# ESP32-C3 register map
Vendor: ESPRESSIF SYSTEMS (SHANGHAI) CO., LTD.; Series: ESP32 C-Series; File version: 18
CPU: RV32IMC r0p0, little endian, no MPU, no FPU, 0 interrupt priority bits
Address unit: 32 bits
Registers are 32-bit, read-write, reset 0x0 unless marked. A register's access mark holds for its fields unless they carry their own. Offsets are from the block's base; [hi:lo] are bit positions.

## EXTMEM — External Memory
Base 0x600C4000
0x00 ICACHE_CTRL — This description will be updated in the near future.
  [0] ICACHE_ENABLE — The bit is used to activate the data cache. 0: disable, 1: enable
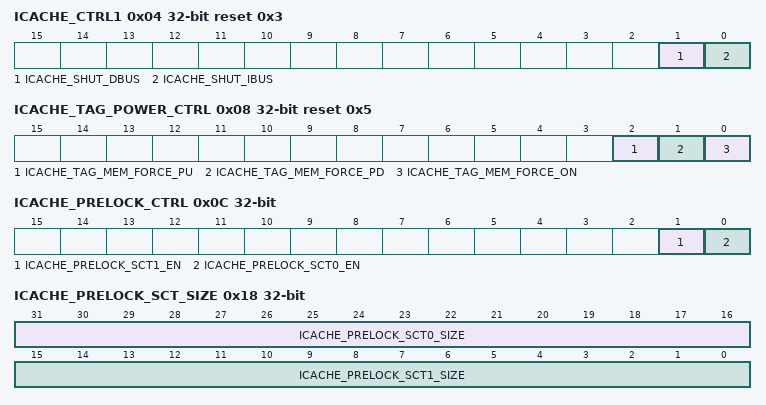
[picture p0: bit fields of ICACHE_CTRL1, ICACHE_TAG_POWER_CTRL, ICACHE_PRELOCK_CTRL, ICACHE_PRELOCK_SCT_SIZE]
0x04 ICACHE_CTRL1 reset 0x3 — This description will be updated in the near future.
  [1] ICACHE_SHUT_DBUS — The bit is used to disable core1 ibus, 0: enable, 1: disable
  [0] ICACHE_SHUT_IBUS — The bit is used to disable core0 ibus, 0: enable, 1: disable
0x08 ICACHE_TAG_POWER_CTRL reset 0x5 — This description will be updated in the near future.
  [2] ICACHE_TAG_MEM_FORCE_PU — The bit is used to power icache tag memory up, 0: follow rtc_lslp, 1: power up
  [1] ICACHE_TAG_MEM_FORCE_PD — The bit is used to power icache tag memory down, 0: follow rtc_lslp, 1: power down
  [0] ICACHE_TAG_MEM_FORCE_ON — The bit is used to close clock gating of icache tag memory. 1: close gating, 0: open clock gating.
0x0C ICACHE_PRELOCK_CTRL — This description will be updated in the near future.
  [1] ICACHE_PRELOCK_SCT1_EN — The bit is used to enable the second section of prelock function.
  [0] ICACHE_PRELOCK_SCT0_EN — The bit is used to enable the first section of prelock function.
0x10 ICACHE_PRELOCK_SCT0_ADDR — This description will be updated in the near future.
  [31:0] ICACHE_PRELOCK_SCT0_ADDR — The bits are used to configure the first start virtual address of data prelock, which is combined with ICACHE_PRELOCK_SCT0_SIZE_REG
0x14 ICACHE_PRELOCK_SCT1_ADDR — This description will be updated in the near future.
  [31:0] ICACHE_PRELOCK_SCT1_ADDR — The bits are used to configure the second start virtual address of data prelock, which is combined with ICACHE_PRELOCK_SCT1_SIZE_REG
0x18 ICACHE_PRELOCK_SCT_SIZE — This description will be updated in the near future.
  [31:16] ICACHE_PRELOCK_SCT0_SIZE — The bits are used to configure the first length of data locking, which is combined with ICACHE_PRELOCK_SCT0_ADDR_REG
  [15:0] ICACHE_PRELOCK_SCT1_SIZE — The bits are used to configure the second length of data locking, which is combined with ICACHE_PRELOCK_SCT1_ADDR_REG
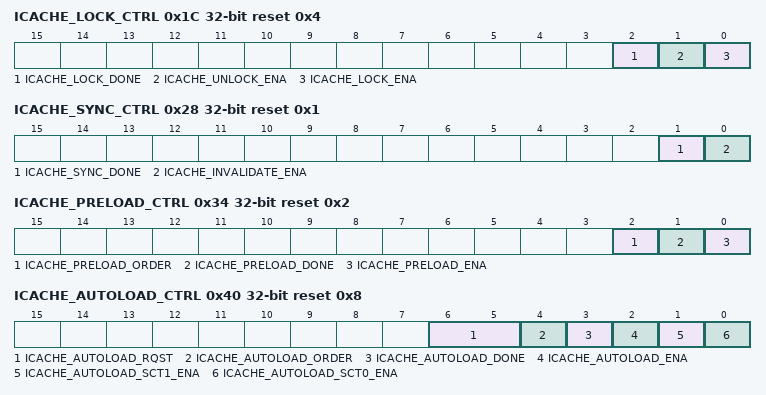
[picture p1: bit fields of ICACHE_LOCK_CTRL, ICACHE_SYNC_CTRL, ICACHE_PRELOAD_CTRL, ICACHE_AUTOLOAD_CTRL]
0x1C ICACHE_LOCK_CTRL access per field reset 0x4 — This description will be updated in the near future.
  [2] ICACHE_LOCK_DONE ro — The bit is used to indicate unlock/lock operation is finished.
  [1] ICACHE_UNLOCK_ENA rw — The bit is used to enable unlock operation. It will be cleared by hardware after unlock operation done.
  [0] ICACHE_LOCK_ENA rw — The bit is used to enable lock operation. It will be cleared by hardware after lock operation done.
0x20 ICACHE_LOCK_ADDR — This description will be updated in the near future.
  [31:0] ICACHE_LOCK_ADDR — The bits are used to configure the start virtual address for lock operations. It should be combined with ICACHE_LOCK_SIZE_REG.
0x24 ICACHE_LOCK_SIZE — This description will be updated in the near future.
  [15:0] ICACHE_LOCK_SIZE — The bits are used to configure the length for lock operations. The bits are the counts of cache block. It should be combined with ICACHE_LOCK_ADDR_REG.
0x28 ICACHE_SYNC_CTRL access per field reset 0x1 — This description will be updated in the near future.
  [1] ICACHE_SYNC_DONE ro — The bit is used to indicate invalidate operation is finished.
  [0] ICACHE_INVALIDATE_ENA rw — The bit is used to enable invalidate operation. It will be cleared by hardware after invalidate operation done.
0x2C ICACHE_SYNC_ADDR — This description will be updated in the near future.
  [31:0] ICACHE_SYNC_ADDR — The bits are used to configure the start virtual address for clean operations. It should be combined with ICACHE_SYNC_SIZE_REG.
0x30 ICACHE_SYNC_SIZE — This description will be updated in the near future.
  [22:0] ICACHE_SYNC_SIZE — The bits are used to configure the length for sync operations. The bits are the counts of cache block. It should be combined with ICACHE_SYNC_ADDR_REG.
0x34 ICACHE_PRELOAD_CTRL access per field reset 0x2 — This description will be updated in the near future.
  [2] ICACHE_PRELOAD_ORDER rw — The bit is used to configure the direction of preload operation. 1: descending, 0: ascending.
  [1] ICACHE_PRELOAD_DONE ro — The bit is used to indicate preload operation is finished.
  [0] ICACHE_PRELOAD_ENA rw — The bit is used to enable preload operation. It will be cleared by hardware after preload operation done.
0x38 ICACHE_PRELOAD_ADDR — This description will be updated in the near future.
  [31:0] ICACHE_PRELOAD_ADDR — The bits are used to configure the start virtual address for preload operation. It should be combined with ICACHE_PRELOAD_SIZE_REG.
0x3C ICACHE_PRELOAD_SIZE — This description will be updated in the near future.
  [15:0] ICACHE_PRELOAD_SIZE — The bits are used to configure the length for preload operation. The bits are the counts of cache block. It should be combined with ICACHE_PRELOAD_ADDR_REG..
0x40 ICACHE_AUTOLOAD_CTRL access per field reset 0x8 — This description will be updated in the near future.
  [6:5] ICACHE_AUTOLOAD_RQST rw — The bits are used to configure trigger conditions for autoload. 0/3: cache miss, 1: cache hit, 2: both cache miss and hit.
  [4] ICACHE_AUTOLOAD_ORDER rw — The bits are used to configure the direction of autoload. 1: descending, 0: ascending.
  [3] ICACHE_AUTOLOAD_DONE ro — The bit is used to indicate autoload operation is finished.
  [2] ICACHE_AUTOLOAD_ENA rw — The bit is used to enable and disable autoload operation. It is combined with icache_autoload_done. 1: enable, 0: disable.
  [1] ICACHE_AUTOLOAD_SCT1_ENA rw — The bits are used to enable the second section for autoload operation.
  [0] ICACHE_AUTOLOAD_SCT0_ENA rw — The bits are used to enable the first section for autoload operation.
0x44 ICACHE_AUTOLOAD_SCT0_ADDR — This description will be updated in the near future.
  [31:0] ICACHE_AUTOLOAD_SCT0_ADDR — The bits are used to configure the start virtual address of the first section for autoload operation. It should be combined with icache_autoload_sct0_ena.
0x48 ICACHE_AUTOLOAD_SCT0_SIZE — This description will be updated in the near future.
  [26:0] ICACHE_AUTOLOAD_SCT0_SIZE — The bits are used to configure the length of the first section for autoload operation. It should be combined with icache_autoload_sct0_ena.
0x4C ICACHE_AUTOLOAD_SCT1_ADDR — This description will be updated in the near future.
  [31:0] ICACHE_AUTOLOAD_SCT1_ADDR — The bits are used to configure the start virtual address of the second section for autoload operation. It should be combined with icache_autoload_sct1_ena.
0x50 ICACHE_AUTOLOAD_SCT1_SIZE — This description will be updated in the near future.
  [26:0] ICACHE_AUTOLOAD_SCT1_SIZE — The bits are used to configure the length of the second section for autoload operation. It should be combined with icache_autoload_sct1_ena.
0x54 IBUS_TO_FLASH_START_VADDR reset 0x42000000 — This description will be updated in the near future.
  [31:0] IBUS_TO_FLASH_START_VADDR — The bits are used to configure the start virtual address of ibus to access flash. The register is used to give constraints to ibus access counter.
0x58 IBUS_TO_FLASH_END_VADDR reset 0x427FFFFF — This description will be updated in the near future.
  [31:0] IBUS_TO_FLASH_END_VADDR — The bits are used to configure the end virtual address of ibus to access flash. The register is used to give constraints to ibus access counter.
0x5C DBUS_TO_FLASH_START_VADDR reset 0x3C000000 — This description will be updated in the near future.
  [31:0] DBUS_TO_FLASH_START_VADDR — The bits are used to configure the start virtual address of dbus to access flash. The register is used to give constraints to dbus access counter.
0x60 DBUS_TO_FLASH_END_VADDR reset 0x3C7FFFFF — This description will be updated in the near future.
  [31:0] DBUS_TO_FLASH_END_VADDR — The bits are used to configure the end virtual address of dbus to access flash. The register is used to give constraints to dbus access counter.
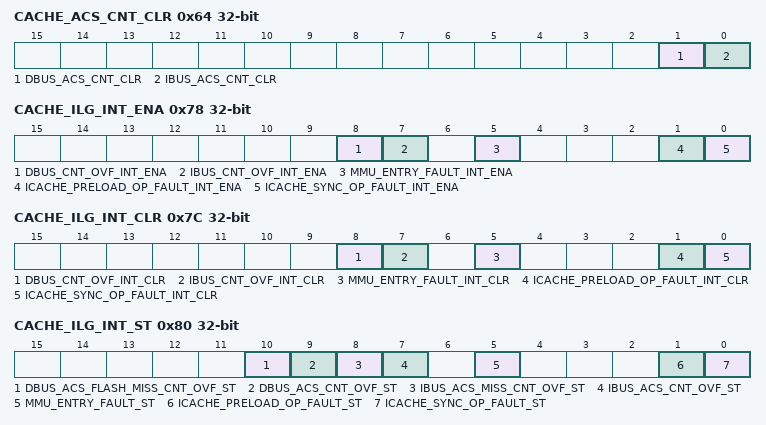
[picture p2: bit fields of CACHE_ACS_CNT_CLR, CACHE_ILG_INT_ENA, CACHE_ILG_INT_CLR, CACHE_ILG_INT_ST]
0x64 CACHE_ACS_CNT_CLR wo — This description will be updated in the near future.
  [1] DBUS_ACS_CNT_CLR — The bit is used to clear dbus counter.
  [0] IBUS_ACS_CNT_CLR — The bit is used to clear ibus counter.
0x68 IBUS_ACS_MISS_CNT ro — This description will be updated in the near future.
  [31:0] IBUS_ACS_MISS_CNT — The bits are used to count the number of the cache miss caused by ibus access flash.
0x6C IBUS_ACS_CNT ro — This description will be updated in the near future.
  [31:0] IBUS_ACS_CNT — The bits are used to count the number of ibus access flash through icache.
0x70 DBUS_ACS_FLASH_MISS_CNT ro — This description will be updated in the near future.
  [31:0] DBUS_ACS_FLASH_MISS_CNT — The bits are used to count the number of the cache miss caused by dbus access flash.
0x74 DBUS_ACS_CNT ro — This description will be updated in the near future.
  [31:0] DBUS_ACS_CNT — The bits are used to count the number of dbus access flash through icache.
0x78 CACHE_ILG_INT_ENA — This description will be updated in the near future.
  [8] DBUS_CNT_OVF_INT_ENA — The bit is used to enable interrupt by dbus counter overflow.
  [7] IBUS_CNT_OVF_INT_ENA — The bit is used to enable interrupt by ibus counter overflow.
  [5] MMU_ENTRY_FAULT_INT_ENA — The bit is used to enable interrupt by mmu entry fault.
  [1] ICACHE_PRELOAD_OP_FAULT_INT_ENA — The bit is used to enable interrupt by preload configurations fault.
  [0] ICACHE_SYNC_OP_FAULT_INT_ENA — The bit is used to enable interrupt by sync configurations fault.
0x7C CACHE_ILG_INT_CLR wo — This description will be updated in the near future.
  [8] DBUS_CNT_OVF_INT_CLR — The bit is used to clear interrupt by dbus counter overflow.
  [7] IBUS_CNT_OVF_INT_CLR — The bit is used to clear interrupt by ibus counter overflow.
  [5] MMU_ENTRY_FAULT_INT_CLR — The bit is used to clear interrupt by mmu entry fault.
  [1] ICACHE_PRELOAD_OP_FAULT_INT_CLR — The bit is used to clear interrupt by preload configurations fault.
  [0] ICACHE_SYNC_OP_FAULT_INT_CLR — The bit is used to clear interrupt by sync configurations fault.
0x80 CACHE_ILG_INT_ST ro — This description will be updated in the near future.
  [10] DBUS_ACS_FLASH_MISS_CNT_OVF_ST — The bit is used to indicate interrupt by dbus access flash miss counter overflow.
  [9] DBUS_ACS_CNT_OVF_ST — The bit is used to indicate interrupt by dbus access flash/spiram counter overflow.
  [8] IBUS_ACS_MISS_CNT_OVF_ST — The bit is used to indicate interrupt by ibus access flash/spiram miss counter overflow.
  [7] IBUS_ACS_CNT_OVF_ST — The bit is used to indicate interrupt by ibus access flash/spiram counter overflow.
  [5] MMU_ENTRY_FAULT_ST — The bit is used to indicate interrupt by mmu entry fault.
  [1] ICACHE_PRELOAD_OP_FAULT_ST — The bit is used to indicate interrupt by preload configurations fault.
  [0] ICACHE_SYNC_OP_FAULT_ST — The bit is used to indicate interrupt by sync configurations fault.
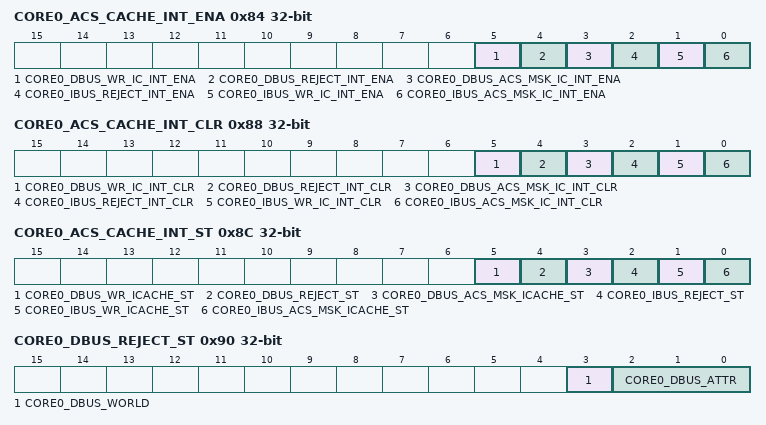
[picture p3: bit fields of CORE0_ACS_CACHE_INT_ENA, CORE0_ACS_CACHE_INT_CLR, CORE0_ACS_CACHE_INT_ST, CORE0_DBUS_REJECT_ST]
0x84 CORE0_ACS_CACHE_INT_ENA — This description will be updated in the near future.
  [5] CORE0_DBUS_WR_IC_INT_ENA — The bit is used to enable interrupt by dbus trying to write icache
  [4] CORE0_DBUS_REJECT_INT_ENA — The bit is used to enable interrupt by authentication fail.
  [3] CORE0_DBUS_ACS_MSK_IC_INT_ENA — The bit is used to enable interrupt by cpu access icache while the corresponding dbus is disabled which include speculative access.
  [2] CORE0_IBUS_REJECT_INT_ENA — The bit is used to enable interrupt by authentication fail.
  [1] CORE0_IBUS_WR_IC_INT_ENA — The bit is used to enable interrupt by ibus trying to write icache
  [0] CORE0_IBUS_ACS_MSK_IC_INT_ENA — The bit is used to enable interrupt by cpu access icache while the corresponding ibus is disabled which include speculative access.
0x88 CORE0_ACS_CACHE_INT_CLR wo — This description will be updated in the near future.
  [5] CORE0_DBUS_WR_IC_INT_CLR — The bit is used to clear interrupt by dbus trying to write icache
  [4] CORE0_DBUS_REJECT_INT_CLR — The bit is used to clear interrupt by authentication fail.
  [3] CORE0_DBUS_ACS_MSK_IC_INT_CLR — The bit is used to clear interrupt by cpu access icache while the corresponding dbus is disabled or icache is disabled which include speculative access.
  [2] CORE0_IBUS_REJECT_INT_CLR — The bit is used to clear interrupt by authentication fail.
  [1] CORE0_IBUS_WR_IC_INT_CLR — The bit is used to clear interrupt by ibus trying to write icache
  [0] CORE0_IBUS_ACS_MSK_IC_INT_CLR — The bit is used to clear interrupt by cpu access icache while the corresponding ibus is disabled or icache is disabled which include speculative access.
0x8C CORE0_ACS_CACHE_INT_ST ro — This description will be updated in the near future.
  [5] CORE0_DBUS_WR_ICACHE_ST — The bit is used to indicate interrupt by dbus trying to write icache
  [4] CORE0_DBUS_REJECT_ST — The bit is used to indicate interrupt by authentication fail.
  [3] CORE0_DBUS_ACS_MSK_ICACHE_ST — The bit is used to indicate interrupt by cpu access icache while the core0_dbus is disabled or icache is disabled which include speculative access.
  [2] CORE0_IBUS_REJECT_ST — The bit is used to indicate interrupt by authentication fail.
  [1] CORE0_IBUS_WR_ICACHE_ST — The bit is used to indicate interrupt by ibus trying to write icache
  [0] CORE0_IBUS_ACS_MSK_ICACHE_ST — The bit is used to indicate interrupt by cpu access icache while the core0_ibus is disabled or icache is disabled which include speculative access.
0x90 CORE0_DBUS_REJECT_ST ro — This description will be updated in the near future.
  [3] CORE0_DBUS_WORLD — The bit is used to indicate the world of CPU access dbus when authentication fail. 0: WORLD0, 1: WORLD1
  [2:0] CORE0_DBUS_ATTR — The bits are used to indicate the attribute of CPU access dbus when authentication fail. 0: invalidate, 1: execute-able, 2: read-able, 4: write-able.
0x94 CORE0_DBUS_REJECT_VADDR ro reset 0xFFFFFFFF — This description will be updated in the near future.
  [31:0] CORE0_DBUS_VADDR — The bits are used to indicate the virtual address of CPU access dbus when authentication fail.
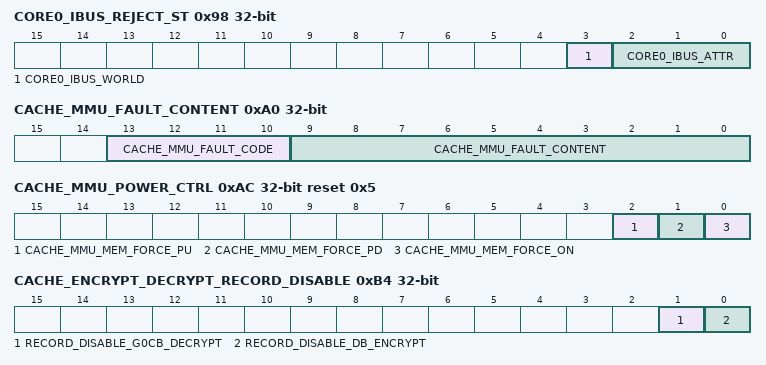
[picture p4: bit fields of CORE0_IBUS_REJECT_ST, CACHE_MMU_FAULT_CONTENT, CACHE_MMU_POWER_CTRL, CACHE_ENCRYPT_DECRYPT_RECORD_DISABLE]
0x98 CORE0_IBUS_REJECT_ST ro — This description will be updated in the near future.
  [3] CORE0_IBUS_WORLD — The bit is used to indicate the world of CPU access ibus when authentication fail. 0: WORLD0, 1: WORLD1
  [2:0] CORE0_IBUS_ATTR — The bits are used to indicate the attribute of CPU access ibus when authentication fail. 0: invalidate, 1: execute-able, 2: read-able
0x9C CORE0_IBUS_REJECT_VADDR ro reset 0xFFFFFFFF — This description will be updated in the near future.
  [31:0] CORE0_IBUS_VADDR — The bits are used to indicate the virtual address of CPU access ibus when authentication fail.
0xA0 CACHE_MMU_FAULT_CONTENT ro — This description will be updated in the near future.
  [13:10] CACHE_MMU_FAULT_CODE — The right-most 3 bits are used to indicate the operations which cause mmu fault occurrence. 0: default, 1: cpu miss, 2: preload miss, 3: writeback, 4: cpu miss evict recovery address, 5: load miss evict recovery address, 6: external dma tx, 7: external dma rx. The most significant bit is used to indicate this operation occurs in which one icache.
  [9:0] CACHE_MMU_FAULT_CONTENT — The bits are used to indicate the content of mmu entry which cause mmu fault..
0xA4 CACHE_MMU_FAULT_VADDR ro — This description will be updated in the near future.
  [31:0] CACHE_MMU_FAULT_VADDR — The bits are used to indicate the virtual address which cause mmu fault..
0xA8 CACHE_WRAP_AROUND_CTRL — This description will be updated in the near future.
  [0] CACHE_FLASH_WRAP_AROUND — The bit is used to enable wrap around mode when read data from flash.
0xAC CACHE_MMU_POWER_CTRL reset 0x5 — This description will be updated in the near future.
  [2] CACHE_MMU_MEM_FORCE_PU — The bit is used to power mmu memory down, 0: follow_rtc_lslp_pd, 1: power up
  [1] CACHE_MMU_MEM_FORCE_PD — The bit is used to power mmu memory down, 0: follow_rtc_lslp_pd, 1: power down
  [0] CACHE_MMU_MEM_FORCE_ON — The bit is used to enable clock gating to save power when access mmu memory, 0: enable, 1: disable
0xB0 CACHE_STATE ro reset 0x1 — This description will be updated in the near future.
  [11:0] ICACHE_STATE — The bit is used to indicate whether icache main fsm is in idle state or not. 1: in idle state, 0: not in idle state
0xB4 CACHE_ENCRYPT_DECRYPT_RECORD_DISABLE — This description will be updated in the near future.
  [1] RECORD_DISABLE_G0CB_DECRYPT — Reserved.
  [0] RECORD_DISABLE_DB_ENCRYPT — Reserved.
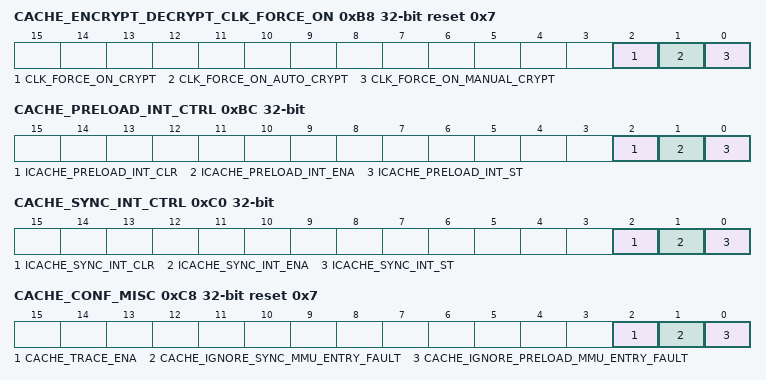
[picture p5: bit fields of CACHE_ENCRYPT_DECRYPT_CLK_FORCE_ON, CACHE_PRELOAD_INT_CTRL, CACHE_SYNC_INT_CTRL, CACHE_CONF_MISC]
0xB8 CACHE_ENCRYPT_DECRYPT_CLK_FORCE_ON reset 0x7 — This description will be updated in the near future.
  [2] CLK_FORCE_ON_CRYPT — The bit is used to close clock gating of external memory encrypt and decrypt clock. 1: close gating, 0: open clock gating.
  [1] CLK_FORCE_ON_AUTO_CRYPT — The bit is used to close clock gating of automatic crypt clock. 1: close gating, 0: open clock gating.
  [0] CLK_FORCE_ON_MANUAL_CRYPT — The bit is used to close clock gating of manual crypt clock. 1: close gating, 0: open clock gating.
0xBC CACHE_PRELOAD_INT_CTRL access per field — This description will be updated in the near future.
  [2] ICACHE_PRELOAD_INT_CLR wo — The bit is used to clear the interrupt by icache pre-load done.
  [1] ICACHE_PRELOAD_INT_ENA rw — The bit is used to enable the interrupt by icache pre-load done.
  [0] ICACHE_PRELOAD_INT_ST ro — The bit is used to indicate the interrupt by icache pre-load done.
0xC0 CACHE_SYNC_INT_CTRL access per field — This description will be updated in the near future.
  [2] ICACHE_SYNC_INT_CLR wo — The bit is used to clear the interrupt by icache sync done.
  [1] ICACHE_SYNC_INT_ENA rw — The bit is used to enable the interrupt by icache sync done.
  [0] ICACHE_SYNC_INT_ST ro — The bit is used to indicate the interrupt by icache sync done.
0xC4 CACHE_MMU_OWNER — This description will be updated in the near future.
  [3:0] CACHE_MMU_OWNER — The bits are used to specify the owner of MMU.bit0/bit2: ibus, bit1/bit3: dbus
0xC8 CACHE_CONF_MISC reset 0x7 — This description will be updated in the near future.
  [2] CACHE_TRACE_ENA — The bit is used to enable cache trace function.
  [1] CACHE_IGNORE_SYNC_MMU_ENTRY_FAULT — The bit is used to disable checking mmu entry fault by sync operation.
  [0] CACHE_IGNORE_PRELOAD_MMU_ENTRY_FAULT — The bit is used to disable checking mmu entry fault by preload operation.
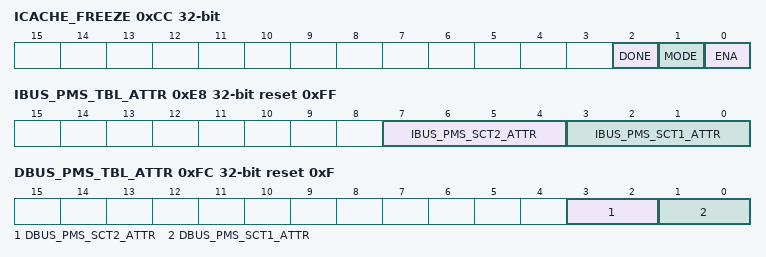
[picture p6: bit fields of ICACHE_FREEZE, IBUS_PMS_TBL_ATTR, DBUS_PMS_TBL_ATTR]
0xCC ICACHE_FREEZE access per field — This description will be updated in the near future.
  [2] DONE ro — The bit is used to indicate icache freeze success
  [1] MODE rw — The bit is used to configure freeze mode, 0: assert busy if CPU miss 1: assert hit if CPU miss
  [0] ENA rw — The bit is used to enable icache freeze mode
0xD0 ICACHE_ATOMIC_OPERATE_ENA reset 0x1 — This description will be updated in the near future.
  [0] ICACHE_ATOMIC_OPERATE_ENA — The bit is used to activate icache atomic operation protection. In this case, sync/lock operation can not interrupt miss-work. This feature does not work during invalidateAll operation.
0xD4 CACHE_REQUEST — This description will be updated in the near future.
  [0] BYPASS — The bit is used to disable request recording which could cause performance issue
0xD8 IBUS_PMS_TBL_LOCK — This description will be updated in the near future.
  [0] IBUS_PMS_LOCK — The bit is used to configure the ibus permission control section boundary0
0xDC IBUS_PMS_TBL_BOUNDARY0 — This description will be updated in the near future.
  [11:0] IBUS_PMS_BOUNDARY0 — The bit is used to configure the ibus permission control section boundary0
0xE0 IBUS_PMS_TBL_BOUNDARY1 reset 0x800 — This description will be updated in the near future.
  [11:0] IBUS_PMS_BOUNDARY1 — The bit is used to configure the ibus permission control section boundary1
0xE4 IBUS_PMS_TBL_BOUNDARY2 reset 0x800 — This description will be updated in the near future.
  [11:0] IBUS_PMS_BOUNDARY2 — The bit is used to configure the ibus permission control section boundary2
0xE8 IBUS_PMS_TBL_ATTR reset 0xFF — This description will be updated in the near future.
  [7:4] IBUS_PMS_SCT2_ATTR — The bit is used to configure attribute of the ibus permission control section2, bit0: fetch in world0, bit1: load in world0, bit2: fetch in world1, bit3: load in world1
  [3:0] IBUS_PMS_SCT1_ATTR — The bit is used to configure attribute of the ibus permission control section1, bit0: fetch in world0, bit1: load in world0, bit2: fetch in world1, bit3: load in world1
0xEC DBUS_PMS_TBL_LOCK — This description will be updated in the near future.
  [0] DBUS_PMS_LOCK — The bit is used to configure the ibus permission control section boundary0
0xF0 DBUS_PMS_TBL_BOUNDARY0 — This description will be updated in the near future.
  [11:0] DBUS_PMS_BOUNDARY0 — The bit is used to configure the dbus permission control section boundary0
0xF4 DBUS_PMS_TBL_BOUNDARY1 reset 0x800 — This description will be updated in the near future.
  [11:0] DBUS_PMS_BOUNDARY1 — The bit is used to configure the dbus permission control section boundary1
0xF8 DBUS_PMS_TBL_BOUNDARY2 reset 0x800 — This description will be updated in the near future.
  [11:0] DBUS_PMS_BOUNDARY2 — The bit is used to configure the dbus permission control section boundary2
0xFC DBUS_PMS_TBL_ATTR reset 0xF — This description will be updated in the near future.
  [3:2] DBUS_PMS_SCT2_ATTR — The bit is used to configure attribute of the dbus permission control section2, bit0: load in world0, bit2: load in world1
  [1:0] DBUS_PMS_SCT1_ATTR — The bit is used to configure attribute of the dbus permission control section1, bit0: load in world0, bit2: load in world1
0x100 CLOCK_GATE reset 0x1 — This description will be updated in the near future.
  [0] CLK_EN — clock gate enable.
0x3FC REG_DATE reset 0x2007160 — This description will be updated in the near future.
  [27:0] DATE — version information

## Notices in the file
Copyright 2024 Espressif Systems (Shanghai) PTE LTD
Licensed under the Apache License, Version 2.0 (the "License");
you may not use this file except in compliance with the License.
You may obtain a copy of the License at
http://www.apache.org/licenses/LICENSE-2.0
Unless required by applicable law or agreed to in writing, software
distributed under the License is distributed on an "AS IS" BASIS,
WITHOUT WARRANTIES OR CONDITIONS OF ANY KIND, either express or implied.
See the License for the specific language governing permissions and
limitations under the License.
